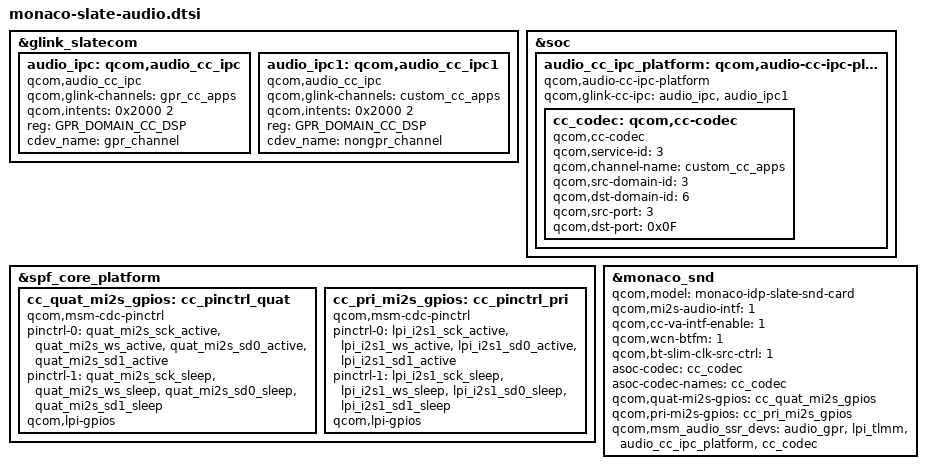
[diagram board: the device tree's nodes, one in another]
#include "monaco-audio.dtsi"
#include "monaco-lpi.dtsi"
&glink_slatecom {
	audio_ipc: qcom,audio_cc_ipc {
			compatible = "qcom,audio_cc_ipc";
			qcom,glink-channels = "gpr_cc_apps";
			qcom,intents = <0x2000 2>;
			reg = <GPR_DOMAIN_CC_DSP>;
			cdev_name = "gpr_channel";
	};

	audio_ipc1: qcom,audio_cc_ipc1 {
			compatible = "qcom,audio_cc_ipc";
			qcom,glink-channels = "custom_cc_apps";
			qcom,intents = <0x2000 2>;
			reg = <GPR_DOMAIN_CC_DSP>;
			cdev_name = "nongpr_channel";
	};
};

&soc {
	audio_cc_ipc_platform: qcom,audio-cc-ipc-platform {
		compatible = "qcom,audio-cc-ipc-platform";
		qcom,glink-cc-ipc = <&audio_ipc>, <&audio_ipc1>;
		cc_codec: qcom,cc-codec {
			compatible = "qcom,cc-codec";
			qcom,service-id = <3>;
			qcom,channel-name = "custom_cc_apps";
			qcom,src-domain-id = <3>;
			qcom,dst-domain-id = <6>;
			qcom,src-port = <3>;
			qcom,dst-port = <0x0F>;
		};
	};
};

&spf_core_platform {
	cc_quat_mi2s_gpios: cc_pinctrl_quat {
		compatible = "qcom,msm-cdc-pinctrl";
		pinctrl-names = "aud_active", "aud_sleep";
		pinctrl-0 = <&quat_mi2s_sck_active &quat_mi2s_ws_active
				&quat_mi2s_sd0_active &quat_mi2s_sd1_active>;

		pinctrl-1 = < &quat_mi2s_sck_sleep &quat_mi2s_ws_sleep
				&quat_mi2s_sd0_sleep &quat_mi2s_sd1_sleep>;
		qcom,lpi-gpios;
	};

	cc_pri_mi2s_gpios: cc_pinctrl_pri {
		compatible = "qcom,msm-cdc-pinctrl";
		pinctrl-names = "aud_active", "aud_sleep";
		pinctrl-0 = <&lpi_i2s1_sck_active &lpi_i2s1_ws_active
				&lpi_i2s1_sd0_active &lpi_i2s1_sd1_active>;

		pinctrl-1 = <&lpi_i2s1_sck_sleep &lpi_i2s1_ws_sleep
				&lpi_i2s1_sd0_sleep &lpi_i2s1_sd1_sleep>;
		qcom,lpi-gpios;
	};
};

&monaco_snd {
	qcom,model = "monaco-idp-slate-snd-card";
	qcom,mi2s-audio-intf = <1>;
	qcom,cc-va-intf-enable = <1>;
	qcom,wcn-btfm = <1>;
	qcom,bt-slim-clk-src-ctrl = <1>;
	asoc-codec  = <&cc_codec>;
	asoc-codec-names = "cc_codec";
	qcom,quat-mi2s-gpios = <&cc_quat_mi2s_gpios>;
	qcom,pri-mi2s-gpios = <&cc_pri_mi2s_gpios>;
	qcom,msm_audio_ssr_devs = <&audio_gpr>, <&lpi_tlmm>,
				  <&audio_cc_ipc_platform>,
				  <&cc_codec>;
};
